VERSION "Sample CAN DBC"

NS_ :

BS_ :

BU_: ECU

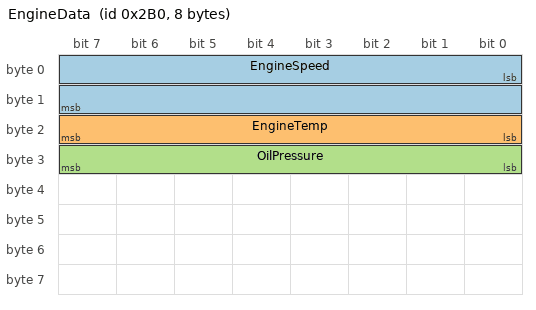
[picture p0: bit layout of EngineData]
BO_ 688 EngineData: 8 ECU
 SG_ EngineSpeed : 0|16@1+ (0.125,0) [0|8000] "rpm" ECU
 SG_ EngineTemp  : 16|8@1+ (1,0) [-40|215] "°C" ECU
 SG_ OilPressure : 24|8@1+ (1,0) [0|255] "kPa" ECU

BO_ 273 VehicleSpeed: 8 ECU
 SG_ Speed       : 0|16@1+ (0.01,0) [0|250] "km/h" ECU
 SG_ GearPos     : 16|8@1+ (1,0) [0|10] "" ECU
